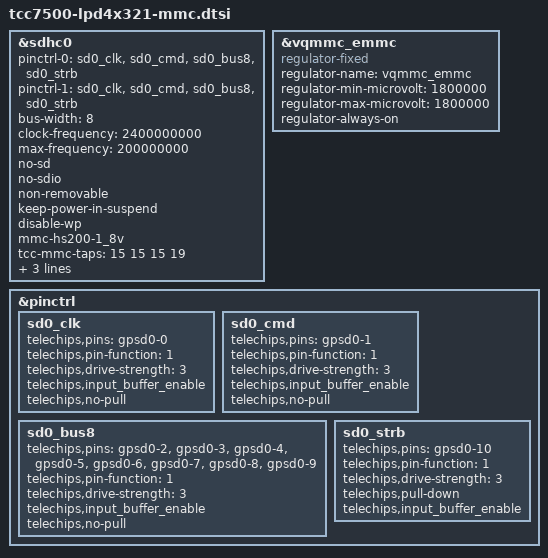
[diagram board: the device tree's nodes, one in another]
// SPDX-License-Identifier: (GPL-2.0-or-later OR MIT)
/*
 * Copyright (C) 2023 Telechips Inc.
 */

/* eMMC */
&sdhc0 {
	pinctrl-names = "default", "sleep";
	pinctrl-0 = <&sd0_clk &sd0_cmd &sd0_bus8 &sd0_strb>;
	pinctrl-1 = <&sd0_clk &sd0_cmd &sd0_bus8 &sd0_strb>;
	status = "okay";
	bus-width = <8>;
	clock-frequency = <2400000000>;
	max-frequency = <200000000>;

	no-sd;
	no-sdio;
	non-removable;
	keep-power-in-suspend;
	disable-wp;

	mmc-hs200-1_8v;

	tcc-mmc-taps = <15 15 15 19>;
	tcc-mmc-hs400-pos-tap = <4>;
	tcc-mmc-hs400-neg-tap = <10>;

	vqmmc-supply = <&vqmmc_emmc>;
};

&vqmmc_emmc {
	compatible = "regulator-fixed";
	regulator-name = "vqmmc_emmc";
	regulator-min-microvolt = <1800000>;
	regulator-max-microvolt = <1800000>;
	regulator-always-on;
};

/* GPIO */
&pinctrl {
	sd0_clk: sd0_clk {
		telechips,pins = "gpsd0-0";
		telechips,pin-function = <1>;
		telechips,drive-strength = <3>;
		telechips,input_buffer_enable;
		telechips,no-pull;
	};

	sd0_cmd: sd0_cmd {
		telechips,pins = "gpsd0-1";
		telechips,pin-function = <1>;
		telechips,drive-strength = <3>;
		telechips,input_buffer_enable;
		telechips,no-pull;
	};

	sd0_bus8: sd0_bus8 {
		telechips,pins = "gpsd0-2", "gpsd0-3", "gpsd0-4", "gpsd0-5",
		                 "gpsd0-6", "gpsd0-7", "gpsd0-8", "gpsd0-9";
		telechips,pin-function = <1>;
		telechips,drive-strength = <3>;
		telechips,input_buffer_enable;
		telechips,no-pull;
	};

	sd0_strb: sd0_strb {
		telechips,pins = "gpsd0-10";
		telechips,pin-function = <1>;
		telechips,drive-strength = <3>;
		telechips,pull-down;
		telechips,input_buffer_enable;
	};
};
